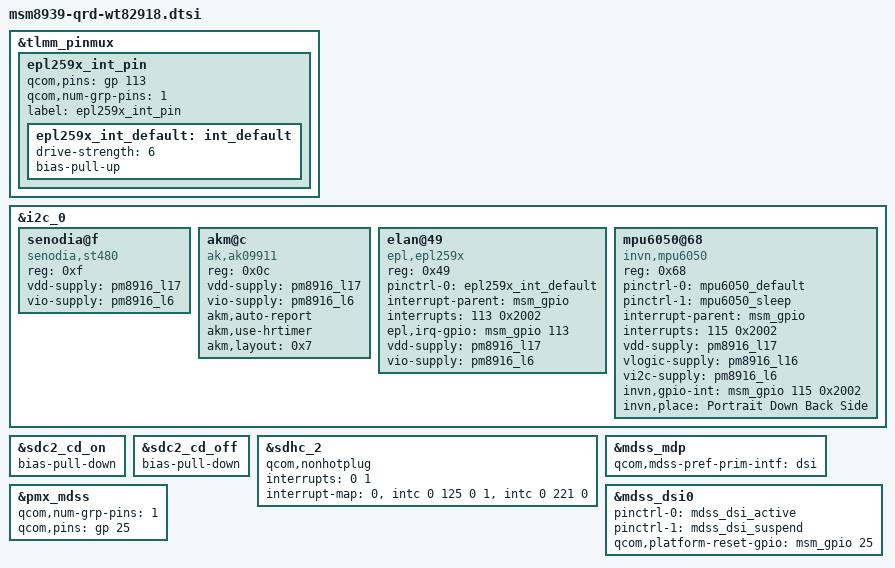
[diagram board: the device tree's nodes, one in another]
/* Copyright (c) 2014-2015, The Linux Foundation. All rights reserved.
 *
 * This program is free software; you can redistribute it and/or modify
 * it under the terms of the GNU General Public License version 2 and
 * only version 2 as published by the Free Software Foundation.
 *
 * This program is distributed in the hope that it will be useful,
 * but WITHOUT ANY WARRANTY; without even the implied warranty of
 * MERCHANTABILITY or FITNESS FOR A PARTICULAR PURPOSE.  See the
 * GNU General Public License for more details.
 */

#include "msm8939-qrd.dtsi"
#include "msm8939-camera-sensor-qrd.dtsi"

&tlmm_pinmux {
	epl259x_int_pin {
		qcom,pins = <&gp 113>;
		qcom,num-grp-pins = <1>;
		label = "epl259x_int_pin";
		epl259x_int_default: int_default {
			drive-strength = <6>;
			bias-pull-up;
		};
	};
};

&i2c_0 { /* BLSP1 QUP2 */
	senodia@f {
		compatible = "senodia,st480";
		reg = <0xf>;
		vdd-supply = <&pm8916_l17>;
		vio-supply = <&pm8916_l6>;
	};

	akm@c {
		compatible = "ak,ak09911";
		reg = <0x0c>;
		vdd-supply = <&pm8916_l17>;
		vio-supply = <&pm8916_l6>;
		akm,auto-report;
                akm,use-hrtimer;
                akm,layout = <0x7>;
	};	

	elan@49 {
		reg = <0x49>;
		compatible = "epl,epl259x";
		pinctrl-names = "default";
		pinctrl-0 = <&epl259x_int_default>;
		interrupt-parent = <&msm_gpio>;
		interrupts = <113 0x2002>;
		epl,irq-gpio  = <&msm_gpio 113 0x2002>;
		vdd-supply = <&pm8916_l17>;
		vio-supply = <&pm8916_l6>;
	};

	mpu6050@68 { /* Gyroscope and accelerometer sensor combo */
		compatible = "invn,mpu6050";
		reg = <0x68>;
		pinctrl-names = "mpu_default","mpu_sleep";
		pinctrl-0 = <&mpu6050_default>;
		pinctrl-1 = <&mpu6050_sleep>;
		interrupt-parent = <&msm_gpio>;
		interrupts = <115 0x2002>;
		vdd-supply = <&pm8916_l17>;
		vlogic-supply = <&pm8916_l16>;
		vi2c-supply = <&pm8916_l6>;
		invn,gpio-int = <&msm_gpio 115 0x2002>;
		invn,place = "Portrait Down Back Side";
	};
};

&sdc2_cd_on {
	/delete-property/ bias-pull-up;
	bias-pull-down;
};

&sdc2_cd_off {
	/delete-property/ bias-disable;
	bias-pull-down;
};

&sdhc_2 {
	qcom,nonhotplug;
	interrupts = <0 1>;
	interrupt-map = <0 &intc 0 125 0
		1 &intc 0 221 0>;
	interrupt-names = "hc_irq", "pwr_irq";
	/delete-property/ cd-gpios;
};

&mdss_mdp {
	qcom,mdss-pref-prim-intf = "dsi";
};

&pmx_mdss {
	qcom,num-grp-pins = <1>;
	qcom,pins = <&gp 25>;
};

&mdss_dsi0 {
	pinctrl-names = "mdss_default", "mdss_sleep";
	pinctrl-0 = <&mdss_dsi_active>;
	pinctrl-1 = <&mdss_dsi_suspend>;

	qcom,platform-reset-gpio = <&msm_gpio 25 0>;
//	qcom,platform-bklight-en-gpio = <&msm_gpio 1 0>;
};

